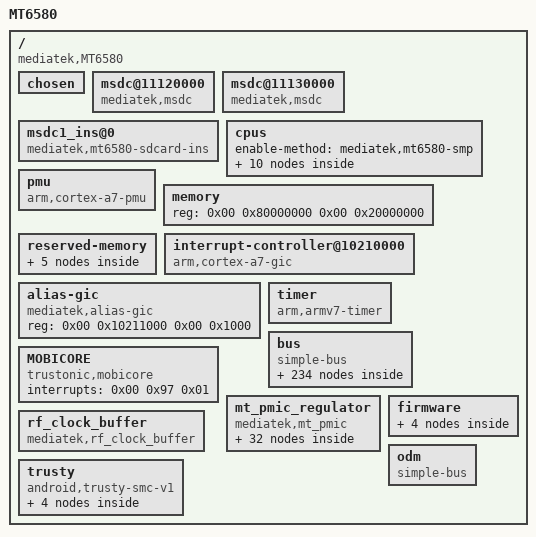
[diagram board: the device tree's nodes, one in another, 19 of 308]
/dts-v1/;

/ {
	model = "MT6580";
	compatible = "mediatek,MT6580";
	interrupt-parent = <0x01>;
	#address-cells = <0x02>;
	#size-cells = <0x02>;

	chosen {
		bootargs = "console=tty0 console=ttyMT3,921600n1 vmalloc=496M androidboot.hardware=mt6580 firmware_class.path=/vendor/firmware loop.max_part=7";
		linux,phandle = <0x2f>;
		phandle = <0x2f>;
	};

	msdc@11120000 {
		compatible = "mediatek,msdc";
		reg = <0x00 0x11120000 0x00 0x10000>;
		interrupts = <0x00 0x26 0x08>;
		index = [00];
		clk_src = [02];
		bus-width = <0x08>;
		max-frequency = <0xbebc200>;
		cap-mmc-highspeed;
		mmc-ddr-1_8v;
		mmc-hs200-1_8v;
		no-sd;
		no-sdio;
		non-removable;
		pinctl = <0x02>;
		pinctl_hs200 = <0x03>;
		register_setting = <0x04>;
		host_function = [00];
		bootable;
		status = "okay";
		vmmc-supply = <0x05>;
		linux,phandle = <0x30>;
		phandle = <0x30>;
	};

	msdc@11130000 {
		compatible = "mediatek,msdc";
		reg = <0x00 0x11130000 0x00 0x10000>;
		interrupts = <0x00 0x27 0x08>;
		index = [01];
		clk_src = [02];
		bus-width = <0x04>;
		max-frequency = <0xbebc200>;
		cap-sd-highspeed;
		sd-uhs-sdr12;
		sd-uhs-sdr25;
		sd-uhs-sdr50;
		sd-uhs-sdr104;
		sd-uhs-ddr50;
		no-mmc;
		no-sdio;
		pinctrl-names = "default\0insert_cfg";
		pinctrl-0 = <0x06>;
		pinctrl-1 = <0x07>;
		pinctl = <0x08>;
		pinctl_sdr104 = <0x09>;
		pinctl_sdr50 = <0x0a>;
		pinctl_ddr50 = <0x0b>;
		register_setting = <0x0c>;
		host_function = [01];
		cd_level = [00];
		cd-gpios = <0x0d 0x03 0x00>;
		status = "okay";
		vmmc-supply = <0x0e>;
		vqmmc-supply = <0x0f>;
		linux,phandle = <0x31>;
		phandle = <0x31>;
	};

	msdc1_ins@0 {
		compatible = "mediatek,mt6580-sdcard-ins";
		linux,phandle = <0x32>;
		phandle = <0x32>;
	};

	cpus {
		#address-cells = <0x01>;
		#size-cells = <0x00>;
		enable-method = "mediatek,mt6580-smp";

		cpu@0 {
			device_type = "cpu";
			compatible = "arm,cortex-a7";
			reg = <0x00>;
			clock-frequency = <0x6553f100>;
			linux,phandle = <0x10>;
			phandle = <0x10>;
		};

		cpu@1 {
			device_type = "cpu";
			compatible = "arm,cortex-a7";
			reg = <0x01>;
			clock-frequency = <0x6553f100>;
			linux,phandle = <0x11>;
			phandle = <0x11>;
		};

		cpu@2 {
			device_type = "cpu";
			compatible = "arm,cortex-a7";
			reg = <0x02>;
			clock-frequency = <0x6553f100>;
			linux,phandle = <0x12>;
			phandle = <0x12>;
		};

		cpu@3 {
			device_type = "cpu";
			compatible = "arm,cortex-a7";
			reg = <0x03>;
			clock-frequency = <0x6553f100>;
			linux,phandle = <0x13>;
			phandle = <0x13>;
		};

		cpu-map {

			cluster0 {

				core0 {
					cpu = <0x10>;
				};

				core1 {
					cpu = <0x11>;
				};

				core2 {
					cpu = <0x12>;
				};

				core3 {
					cpu = <0x13>;
				};
			};
		};
	};

	pmu {
		compatible = "arm,cortex-a7-pmu";
		interrupts = <0x00 0x04 0x08 0x00 0x05 0x08 0x00 0x06 0x08 0x00 0x07 0x08>;
	};

	memory {
		device_type = "memory";
		reg = <0x00 0x80000000 0x00 0x20000000>;
	};

	reserved-memory {
		#address-cells = <0x02>;
		#size-cells = <0x02>;
		ranges;
		linux,phandle = <0x33>;
		phandle = <0x33>;

		consys-reserve-memory {
			compatible = "mediatek,consys-reserve-memory";
			no-map;
			size = <0x00 0x200000>;
			alignment = <0x00 0x200000>;
		};

		reserve-memory-ccci_md1 {
			compatible = "mediatek,reserve-memory-ccci_md1";
			no-map;
			size = <0x00 0x1800000>;
			alignment = <0x00 0x2000000>;
			alloc-ranges = <0x00 0x80000000 0x00 0x80000000>;
		};

		pstore-reserved-memory@83f10000 {
			compatible = "mediatek,pstore";
			reg = <0x00 0x83f10000 0x00 0xe0000>;
		};

		ram_console-reserved-memory@83f00000 {
			compatible = "mediatek,ram_console";
			reg = <0x00 0x83f00000 0x00 0x10000>;
		};

		minirdump-reserved-memory@83ff0000 {
			compatible = "mediatek, minirdump";
			reg = <0x00 0x83ff0000 0x00 0x10000>;
		};
	};

	interrupt-controller@10210000 {
		compatible = "arm,cortex-a7-gic";
		#interrupt-cells = <0x03>;
		#address-cells = <0x00>;
		interrupt-controller;
		reg = <0x00 0x10211000 0x00 0x1000 0x00 0x10212000 0x00 0x1000 0x00 0x10200100 0x00 0x1000>;
		interrupts = <0x01 0x09 0xf04>;
		linux,phandle = <0x01>;
		phandle = <0x01>;
	};

	alias-gic {
		compatible = "mediatek,alias-gic";
		reg = <0x00 0x10211000 0x00 0x1000>;
	};

	timer {
		compatible = "arm,armv7-timer";
		interrupts = <0x01 0x0d 0x08 0x01 0x0e 0x08 0x01 0x0b 0x08 0x01 0x0a 0x08>;
		clock-frequency = <0xc65d40>;
	};

	bus {
		compatible = "simple-bus";
		#address-cells = <0x01>;
		#size-cells = <0x01>;
		ranges = <0x00 0x00 0x00 0xffffffff>;
		linux,phandle = <0x34>;
		phandle = <0x34>;

		chipid@08000000 {
			compatible = "mediatek,chipid";
			reg = <0x8000000 0x04 0x8000004 0x04 0x8000008 0x04 0x800000c 0x04>;
		};

		TOPCKGEN@0x10000000 {
			compatible = "mediatek,TOPCKGEN";
			reg = <0x10000000 0x1000>;
		};

		INFRACFG_AO@0x10001000 {
			compatible = "mediatek,INFRACFG_AO";
			reg = <0x10001000 0x1000>;
		};

		bat_meter {
			compatible = "mediatek,bat_meter";
			linux,phandle = <0x35>;
			phandle = <0x35>;
		};

		BAT_NOTIFY {
			compatible = "mediatek,bat_notify";
		};

		bat_comm {
			compatible = "mediatek,battery";
			linux,phandle = <0x36>;
			phandle = <0x36>;
		};

		keypad@10002000 {
			compatible = "mediatek,kp";
			reg = <0x10002000 0x1000>;
			interrupts = <0x00 0x6d 0x02>;
			linux,phandle = <0x37>;
			phandle = <0x37>;
		};

		PERICFG@0x10003000 {
			compatible = "mediatek,PERICFG";
			reg = <0x10003000 0x1000>;
		};

		RESERVED@0x10004000 {
			compatible = "mediatek,RESERVED";
			reg = <0x10004000 0x1000>;
		};

		gpio {
			compatible = "mediatek,gpio_usage_mapping";
			linux,phandle = <0x38>;
			phandle = <0x38>;
		};

		gpio@0x10005000 {
			compatible = "mediatek,gpio";
			reg = <0x10005000 0x1000>;
			linux,phandle = <0x39>;
			phandle = <0x39>;
		};

		SLEEP@0x10006000 {
			compatible = "mediatek,SLEEP";
			reg = <0x10006000 0x1000>;
			interrupts = <0x00 0x58 0x08 0x00 0x59 0x08 0x00 0x5a 0x08 0x00 0x5b 0x08>;
		};

		TOPRGU@0x10007000 {
			compatible = "mediatek,TOPRGU";
			reg = <0x10007000 0x1000>;
			interrupts = <0x00 0x9d 0x02>;
		};

		APXGPT@0x10008000 {
			compatible = "mediatek,APXGPT";
			reg = <0x10008000 0x1000>;
			interrupts = <0x00 0x5c 0x08>;
			clock-frequency = <0xc65d40>;
		};

		EFUSEC@0x10009000 {
			compatible = "mediatek,EFUSEC";
			reg = <0x10009000 0x1000>;
		};

		hacc@0x1000A000 {
			compatible = "mediatek,hacc";
			reg = <0x1000a000 0x1000>;
			interrupts = <0x00 0x6e 0x00>;
		};

		cpu_dbgapb@10170000 {
			compatible = "mediatek,hw_dbg";
			num = <0x04>;
			reg = <0x10170000 0x2000 0x10172000 0x2000 0x10174000 0x2000 0x10176000 0x2000>;
			linux,phandle = <0x3a>;
			phandle = <0x3a>;
		};

		eintc@1000b000 {
			compatible = "mediatek,mt-eic";
			reg = <0x1000b000 0x1000>;
			interrupts = <0x00 0x5e 0x04>;
			#interrupt-cells = <0x02>;
			interrupt-controller;
			mediatek,max_eint_num = <0x1a>;
			mediatek,mapping_table_entry = <0x53>;
			mediatek,mapping_table = <0x00 0x00 0x01 0x01 0x02 0x02 0x03 0x03 0x04 0x04 0x05 0x05 0x06 0x06 0x07 0x07 0x08 0x08 0x09 0x09 0x0a 0x0a 0x0b 0x0b 0x0c 0x0c 0x0d 0x0d 0x0e 0x0e 0x0f 0x0f 0x10 0x00 0x11 0x01 0x12 0x02 0x13 0x03 0x14 0x04 0x15 0x05 0x16 0x06 0x17 0x07 0x18 0x08 0x19 0x09 0x1a 0x0a 0x1b 0x0b 0x1c 0x0c 0x1d 0x0d 0x1e 0x0e 0x1f 0x0f 0x20 0x00 0x21 0x01 0x22 0x02 0x23 0x03 0x24 0x04 0x25 0x05 0x26 0x06 0x27 0x07 0x28 0x08 0x29 0x09 0x2a 0x0a 0x2b 0x0b 0x2c 0x0c 0x2d 0x0d 0x2e 0x0e 0x2f 0x0f 0x30 0x00 0x31 0x01 0x32 0x02 0x33 0x03 0x34 0x03 0x35 0x04 0x36 0x05 0x37 0x06 0x38 0x07 0x39 0x08 0x3a 0x0a 0x3b 0x0b 0x3c 0x0c 0x3d 0x0d 0x3e 0x0e 0x3f 0x0f 0x40 0x00 0x41 0x01 0x42 0x02 0x43 0x03 0x44 0x10 0x45 0x04 0x46 0x05 0x47 0x06 0x48 0x07 0x49 0x08 0x4a 0x09 0x4b 0x0a 0x4c 0x0b 0x4d 0x0c 0x4e 0x0d 0x51 0x00 0x52 0x01 0x53 0x02 0x54 0x03>;
			mediatek,builtin_entry = <0x0b>;
			mediatek,builtin_mapping = <0x00 0x03 0x14 0x01 0x03 0x12 0x07 0x04 0x14 0x08 0x04 0x12 0x09 0x03 0x14 0x0a 0x03 0x12 0x18 0x05 0x14 0x19 0x05 0x12 0x4d 0x02 0x14 0x4e 0x02 0x12 0x0d 0x01 0x11>;
			linux,phandle = <0x14>;
			phandle = <0x14>;

			pmic@13 {
				compatible = "mediatek, pmic-eint";
				interrupt-parent = <0x14>;
				interrupts = <0x0d 0x04>;
				debounce = <0x0d 0x3e8>;
			};
		};

		ap_ccif0@1000C000 {
			compatible = "mediatek,ap_ccif0";
			reg = <0x1000c000 0x1000 0x1000d000 0x1000>;
			interrupts = <0x00 0x5d 0x08 0x00 0x98 0x02>;
			mediatek,ccif_capability = <0x02>;
			mediatek,md_smem_size = <0x200000>;
			linux,phandle = <0x3b>;
			phandle = <0x3b>;
		};

		MCUSYS_CFGREG@0x1020000 {
			compatible = "mediatek,MCUSYS_CFGREG_BASE";
			reg = <0x1020000 0x200>;
		};

		mcucfg@10200000 {
			compatible = "mediatek,mt6580-mcucfg";
			reg = <0x10200000 0x200>;
			linux,phandle = <0x3c>;
			phandle = <0x3c>;
		};

		AES@0x1000E000 {
			compatible = "mediatek,AES";
			reg = <0x1000e000 0x1000>;
		};

		PWRAP@0x1000F000 {
			compatible = "mediatek,PWRAP";
			reg = <0x1000f000 0x1000>;
			interrupts = <0x00 0x6c 0x00>;
		};

		DEVAPC_AO@0x10010000 {
			compatible = "mediatek,DEVAPC_AO";
			reg = <0x10010000 0x1000>;
		};

		MIPI_CONFG@0x10011000 {
			compatible = "mediatek,MIPI_CONFG";
			reg = <0x10011000 0x1000>;
		};

		INFRA_MBIST@0x10012000 {
			compatible = "mediatek,INFRA_MBIST";
			reg = <0x10012000 0x1000>;
		};

		RESERVED@0x10013000 {
			compatible = "mediatek,RESERVED";
			reg = <0x10013000 0x1000>;
		};

		IOCFG_T@0x10014000 {
			compatible = "mediatek,IOCFG_T";
			reg = <0x10014000 0x1000>;
		};

		IOCFG_B@0x10015000 {
			compatible = "mediatek,IOCFG_B";
			reg = <0x10015000 0x1000>;
		};

		IOCFG_L@0x10016000 {
			compatible = "mediatek,IOCFG_L";
			reg = <0x10016000 0x1000>;
		};

		IOCFG_R@0x10017000 {
			compatible = "mediatek,IOCFG_R";
			reg = <0x10017000 0x1000>;
		};

		APMIXED@0x10018000 {
			compatible = "mediatek,APMIXED";
			reg = <0x10018000 0x1000>;
		};

		MCUCFG@0x10200000 {
			compatible = "mediatek,MCUCFG";
			reg = <0x10200000 0x1000>;
		};

		INFRACFG@0x10201000 {
			compatible = "mediatek,INFRACFG";
			reg = <0x10201000 0x1000>;
		};

		sys_cirq@10202000 {
			compatible = "mediatek,mt6580-sys_cirq\0mediatek,mt6735-sys_cirq";
			reg = <0x10202000 0x1000>;
			interrupts = <0x00 0x9e 0x08>;
			mediatek,cirq_num = <0x7e>;
			mediatek,spi_start_offset = <0x20>;
			linux,phandle = <0x3d>;
			phandle = <0x3d>;
		};

		m4u@10203000 {
			cell-index = <0x00>;
			compatible = "mediatek,m4u";
			reg = <0x10203000 0x1000>;
			interrupts = <0x00 0x51 0x08>;
		};

		DEVAPC@0x10204000 {
			compatible = "mediatek,DEVAPC";
			reg = <0x10204000 0x1000>;
			interrupts = <0x00 0x4a 0x08>;
		};

		EMI@0x10205000 {
			compatible = "mediatek,EMI";
			reg = <0x10205000 0x1000>;
			interrupts = <0x00 0x4c 0x04>;
		};

		DRAMC_NAO@0x10206000 {
			compatible = "mediatek,DRAMC_NAO";
			reg = <0x10206000 0x1000>;
		};

		DRAMC0@0x10207000 {
			compatible = "mediatek,DRAMC0";
			reg = <0x10207000 0x1000>;
		};

		DDRPHY@0x10208000 {
			compatible = "mediatek,DDRPHY";
			reg = <0x10208000 0x1000>;
		};

		SRAMROM@0x10209000 {
			compatible = "mediatek,SRAMROM";
			reg = <0x10209000 0x1000>;
		};

		gce@1020a000 {
			compatible = "mediatek,gce";
			reg = <0x1020a000 0x1000>;
			interrupts = <0x00 0x55 0x08 0x00 0x56 0x08>;
			disp_mutex_reg = <0x14015000 0x1000>;
			g3d_config_base = <0x13000000 0x00 0xffff0000>;
			mmsys_config_base = <0x14000000 0x01 0xffff0000>;
			disp_dither_base = <0x14010000 0x02 0xffff0000>;
			mm_na_base = <0x14020000 0x03 0xffff0000>;
			imgsys_base = <0x15000000 0x04 0xffff0000>;
			vdec_gcon_base = <0x16000000 0x05 0xffff0000>;
			venc_gcon_base = <0x17000000 0x06 0xffff0000>;
			conn_peri_base = <0x18000000 0x07 0xffff0000>;
			topckgen_base = <0x10000000 0x08 0xffff0000>;
			kp_base = <0x10010000 0x09 0xffff0000>;
			scp_sram_base = <0x10020000 0x0a 0xffff0000>;
			infra_na3_base = <0x10030000 0x0b 0xffff0000>;
			infra_na4_base = <0x10040000 0x0c 0xffff0000>;
			scp_base = <0x10050000 0x0d 0xffff0000>;
			mcucfg_base = <0x10200000 0x0e 0xffff0000>;
			gcpu_base = <0x10210000 0x0f 0xffff0000>;
			usb0_base = <0x11200000 0x10 0xffff0000>;
			usb_sif_base = <0x11210000 0x11 0xffff0000>;
			audio_base = <0x11220000 0x12 0xffff0000>;
			msdc0_base = <0x11230000 0x13 0xffff0000>;
			msdc1_base = <0x11240000 0x14 0xffff0000>;
			msdc2_base = <0x11250000 0x15 0xffff0000>;
			msdc3_base = <0x11260000 0x16 0xffff0000>;
			pwm_sw_base = <0x1100f000 0x63 0xfffff000>;
			mdp_rdma0_sof = <0x00>;
			mdp_rsz0_sof = <0x01>;
			mdp_rsz1_sof = <0x02>;
			mdp_tdshp_sof = <0x03>;
			mdp_wdma_sof = <0x04>;
			mdp_wrot_sof = <0x05>;
			disp_ovl0_sof = <0x06>;
			disp_rdma0_sof = <0x08>;
			disp_wdma0_sof = <0x0a>;
			disp_color_sof = <0x0c>;
			disp_aal_sof = <0x0d>;
			disp_gamma_sof = <0x0e>;
			disp_dither_sof = <0x0f>;
			disp_pwm0_sof = <0x11>;
			mdp_rdma0_frame_done = <0x12>;
			mdp_rsz0_frame_done = <0x13>;
			mdp_rsz1_frame_done = <0x14>;
			mdp_tdshp_frame_done = <0x15>;
			mdp_wdma_frame_done = <0x16>;
			mdp_wrot_write_frame_done = <0x17>;
			mdp_wrot_read_frame_done = <0x18>;
			disp_ovl0_frame_done = <0x19>;
			disp_rdma0_frame_done = <0x1b>;
			disp_wdma0_frame_done = <0x1d>;
			disp_color_frame_done = <0x1f>;
			disp_aal_frame_done = <0x20>;
			disp_gamma_frame_done = <0x21>;
			disp_dither_frame_done = <0x22>;
			disp_dsi0_frame_done = <0x25>;
			stream_done_0 = <0x26>;
			stream_done_1 = <0x27>;
			stream_done_2 = <0x28>;
			stream_done_3 = <0x29>;
			stream_done_4 = <0x2a>;
			stream_done_5 = <0x2b>;
			stream_done_6 = <0x2c>;
			stream_done_7 = <0x2d>;
			stream_done_8 = <0x2e>;
			stream_done_9 = <0x2f>;
			buf_underrun_event_0 = <0x30>;
			dsi0_te_event = <0x32>;
			isp_frame_done_p2_1 = <0x42>;
			isp_frame_done_p2_0 = <0x43>;
			seninf_cam0_fifo_full = <0x49>;
			apxgpt2_count = <0x10008028>;
		};

		bus_dbg@1020b000 {
			compatible = "mediatek,bus_dbg-v2";
			reg = <0x1020b000 0x1000>;
			interrupts = <0x00 0x49 0x08>;
			two_stage_timeout = <0x01>;
		};

		trng@0x1020f000 {
			compatible = "mediatek,trng";
			reg = <0x1020c000 0x1000 0x10001000 0x1000>;
			interrupts = <0x00 0x57 0x08>;
		};

		MCUCFG_BIU@0x1020D000 {
			compatible = "mediatek,MCUCFG_BIU";
			reg = <0x1020d000 0x1000>;
		};

		DBGSYS_DEM@0x1011A000 {
			compatible = "mediatek,DBGSYS_DEM";
			reg = <0x1011a000 0x1000>;
		};

		DBGSYS_CTI@0x10112000 {
			compatible = "mediatek,DBGSYS_CTI";
			reg = <0x10112000 0x1000>;
		};

		DBGSYS_DAPROM@0x10110000 {
			compatible = "mediatek,DBGSYS_DAPROM";
			reg = <0x10110000 0x1000>;
		};

		DBGSYS_CPU@0x10160000 {
			compatible = "mediatek,DBGSYS_CPU";
			reg = <0x10160000 0x20000>;
		};

		DBGSYS_MDSYS@0x10120000 {
			compatible = "mediatek,DBGSYS_MDSYS";
			reg = <0x10120000 0x10000>;
		};

		dma@0x11000000 {
			compatible = "mediatek,ap_dma";
			reg = <0x11000000 0x1000>;
			interrupts = <0x00 0x30 0x08>;
			linux,phandle = <0x3e>;
			phandle = <0x3e>;
		};

		NFI@0x11001000 {
			compatible = "mediatek,NFI";
			reg = <0x11001000 0x1000>;
			interrupts = <0x00 0x2f 0x08>;
		};

		NFIECC@0x11002000 {
			compatible = "mediatek,NFIECC";
			reg = <0x11002000 0x1000>;
			interrupts = <0x00 0x2e 0x08>;
		};

		adc_hw@11003000 {
			compatible = "mediatek,mt6735-auxadc";
			reg = <0x11003000 0x1000>;
			interrupts = <0x00 0x23 0x02>;
			linux,phandle = <0x3f>;
			phandle = <0x3f>;
		};

		FHCTL@0x11004000 {
			compatible = "mediatek,FHCTL";
			reg = <0x11004000 0x1000>;
		};

		AP_UART0@0x11005000 {
			cell-index = <0x00>;
			skip_pinmux_clk = <0x01>;
			compatible = "mediatek,AP_UART0";
			reg = <0x11005000 0x1000>;
			interrupts = <0x00 0x2c 0x08>;
		};

		AP_UART1@0x11006000 {
			cell-index = <0x01>;
			skip_pinmux_clk = <0x01>;
			compatible = "mediatek,AP_UART1";
			reg = <0x11006000 0x1000>;
			interrupts = <0x00 0x2d 0x08>;
		};

		AP_DMA_UART0_TX@0x11000480 {
			compatible = "mediatek,AP_DMA_UART0_TX";
			reg = <0x11000480 0x80>;
			interrupts = <0x00 0x38 0x08>;
		};

		AP_DMA_UART0_RX@0x11000500 {
			compatible = "mediatek,AP_DMA_UART0_RX";
			reg = <0x11000500 0x80>;
			interrupts = <0x00 0x39 0x08>;
		};

		AP_DMA_UART1_TX@0x11000580 {
			compatible = "mediatek,AP_DMA_UART1_TX";
			reg = <0x11000580 0x80>;
			interrupts = <0x00 0x3a 0x08>;
		};

		AP_DMA_UART1_RX@0x11000600 {
			compatible = "mediatek,AP_DMA_UART1_RX";
			reg = <0x11000600 0x80>;
			interrupts = <0x00 0x3b 0x08>;
		};

		pwm@11008000 {
			compatible = "mediatek,pwm";
			reg = <0x11008000 0x1000>;
			interrupts = <0x00 0x24 0x08>;
		};

		syscfg_pctl_a@0x10005000 {
			compatible = "mediatek,mt6580-pctl-a-syscfg\0syscon";
			reg = <0x10211000 0x1000>;
			linux,phandle = <0x15>;
			phandle = <0x15>;
		};

		pinctrl@0x10005000 {
			compatible = "mediatek,mt6580-pinctrl";
			reg = <0x10005000 0x1000>;
			mediatek,pctl-regmap = <0x15>;
			pins-are-numbered;
			gpio-controller;
			#gpio-cells = <0x02>;
			linux,phandle = <0x0d>;
			phandle = <0x0d>;

			msdc0@default {
				linux,phandle = <0x02>;
				phandle = <0x02>;

				pins_cmd {
					drive-strength = [02];
				};

				pins_dat {
					drive-strength = [02];
				};

				pins_clk {
					drive-strength = [02];
				};

				pins_rst {
					drive-strength = [02];
				};

				pins_ds {
					drive-strength = [02];
				};
			};

			msdc0@hs200 {
				linux,phandle = <0x03>;
				phandle = <0x03>;

				pins_cmd {
					drive-strength = [02];
				};

				pins_dat {
					drive-strength = [02];
				};

				pins_clk {
					drive-strength = [02];
				};

				pins_rst {
					drive-strength = [02];
				};

				pins_ds {
					drive-strength = [02];
				};
			};

			msdc0@register_default {
				cmd_edge = [00];
				rdata_edge = [00];
				wdata_edge = [00];
				linux,phandle = <0x04>;
				phandle = <0x04>;
			};

			mmc1_ins_default {
				linux,phandle = <0x06>;
				phandle = <0x06>;
			};

			mmc1_ins_cfg {
				linux,phandle = <0x07>;
				phandle = <0x07>;

				pins_insert {
					pins = <0x306>;
					input-schmitt-enable = <0x01>;
					slew-rate = <0x00>;
					bias-pull-up = <0x00>;
				};
			};

			msdc1@default {
				linux,phandle = <0x08>;
				phandle = <0x08>;

				pins_cmd {
					drive-strength = [03];
				};

				pins_dat {
					drive-strength = [03];
				};

				pins_clk {
					drive-strength = [03];
				};
			};

			msdc1@sdr104 {
				linux,phandle = <0x09>;
				phandle = <0x09>;

				pins_cmd {
					drive-strength = [02];
				};

				pins_dat {
					drive-strength = [02];
				};

				pins_clk {
					drive-strength = [03];
				};
			};

			msdc1@sdr50 {
				linux,phandle = <0x0a>;
				phandle = <0x0a>;

				pins_cmd {
					drive-strength = [02];
				};

				pins_dat {
					drive-strength = [02];
				};

				pins_clk {
					drive-strength = [03];
				};
			};

			msdc1@ddr50 {
				linux,phandle = <0x0b>;
				phandle = <0x0b>;

				pins_cmd {
					drive-strength = [02];
				};

				pins_dat {
					drive-strength = [02];
				};

				pins_clk {
					drive-strength = [03];
				};
			};

			msdc1@register_default {
				cmd_edge = [00];
				rdata_edge = [00];
				wdata_edge = [00];
				linux,phandle = <0x0c>;
				phandle = <0x0c>;
			};
		};

		i2c@11009000 {
			compatible = "mediatek,mt6580-i2c\0mediatek,i2c0";
			cell-index = <0x00>;
			reg = <0x11009000 0x1000>;
			interrupts = <0x00 0x28 0x08 0x00 0x32 0x08>;
			clock-div = <0x0a>;
			#address-cells = <0x01>;
			#size-cells = <0x00>;
			linux,phandle = <0x40>;
			phandle = <0x40>;
		};

		i2c@1100a000 {
			compatible = "mediatek,mt6580-i2c\0mediatek,i2c1";
			cell-index = <0x01>;
			reg = <0x1100a000 0x1000>;
			interrupts = <0x00 0x29 0x08 0x00 0x33 0x08>;
			clock-div = <0x0a>;
			#address-cells = <0x01>;
			#size-cells = <0x00>;
			linux,phandle = <0x41>;
			phandle = <0x41>;
		};

		i2c@1100b000 {
			compatible = "mediatek,mt6580-i2c\0mediatek,i2c2";
			cell-index = <0x02>;
			reg = <0x1100b000 0x1000>;
			interrupts = <0x00 0x2a 0x08 0x00 0x34 0x08>;
			clock-div = <0x0a>;
			#address-cells = <0x01>;
			#size-cells = <0x00>;
			linux,phandle = <0x42>;
			phandle = <0x42>;
		};

		touch@0 {
			compatible = "mediatek,touch";
			vtouch-supply = <0x16>;
			linux,phandle = <0x43>;
			phandle = <0x43>;
		};

		accdet {
			compatible = "mediatek,pmic-accdet";
			linux,phandle = <0x44>;
			phandle = <0x44>;
		};

		gse_1 {
			compatible = "mediatek, gse_1-eint";
			status = "disabled";
			linux,phandle = <0x45>;
			phandle = <0x45>;
		};

		spi@1100c000 {
			compatible = "mediatek,mt6580-spi";
			cell-index = <0x00>;
			reg = <0x1100c000 0x1000>;
			interrupts = <0x00 0x40 0x08>;
			mediatek,spi-padmacro = <0x00>;
		};

		THERM_CTRL@0x1100D000 {
			compatible = "mediatek,THERM_CTRL";
			reg = <0x1100d000 0x1000>;
			interrupts = <0x00 0x25 0x08>;
		};

		btif@1100e000 {
			compatible = "mediatek,btif";
			#address-cells = <0x02>;
			#size-cells = <0x02>;
			reg = <0x1100e000 0x1000 0x11000380 0x80 0x11000400 0x80>;
			interrupts = <0x00 0x43 0x08 0x00 0x36 0x08 0x00 0x37 0x08>;
		};

		gps {
			compatible = "mediatek,gps";
		};

		BTCVSD@0x10001000 {
			compatible = "mediatek,audio_bt_cvsd";
			offset = <0xc00 0x02 0xfd0 0xfd4 0xfd8>;
			reg = <0x10001000 0x1000 0x18000000 0x10000 0x18080000 0x8000>;
			interrupts = <0x00 0x99 0x08>;
		};

		consys@18070000 {
			compatible = "mediatek,mt6580-consys";
			reg = <0x18070000 0x200 0x10007000 0x100 0x10000000 0x2000 0x10006000 0x1000 0x10005000 0x1000>;
			interrupts = <0x00 0x9a 0x08 0x00 0x9c 0x08>;
			vcn18-supply = <0x17>;
			vcn28-supply = <0x18>;
			vcn33_bt-supply = <0x19>;
			vcn33_wifi-supply = <0x1a>;
			linux,phandle = <0x46>;
			phandle = <0x46>;
		};

		WIFI@0x180F0000 {
			compatible = "mediatek,WIFI";
			reg = <0x180f0000 0x5c>;
			interrupts = <0x00 0x9b 0x08>;
		};

		DISP_PWM@0x1100F000 {
			compatible = "mediatek,DISP_PWM";
			reg = <0x1100f000 0x1000>;
			interrupts = <0x00 0x21 0x08>;
		};

		USB0@0x11100000 {
			compatible = "mediatek,USB0";
			cell-index = <0x00>;
			reg = <0x11100000 0x10000 0x11110000 0x10000>;
			interrupts = <0x00 0x20 0x08>;
			mode = <0x02>;
			multipoint = <0x01>;
			dyn_fifo = <0x01>;
			soft_con = <0x01>;
			dma = <0x01>;
			num_eps = <0x10>;
			dma_channels = <0x08>;
			linux,phandle = <0x47>;
			phandle = <0x47>;
		};

		usbiddig {
			compatible = "mediatek,usb_iddig_eint";
			linux,phandle = <0x48>;
			phandle = <0x48>;
		};

		usbphy@0 {
			compatible = "usb-nop-xceiv";
			linux,phandle = <0x49>;
			phandle = <0x49>;
		};

		audio@11140000 {
			compatible = "mediatek,audio";
			reg = <0x11140000 0x10000>;
			interrupts = <0x00 0x50 0x08>;
		};

		mt_soc_dl1_pcm@11140000 {
			compatible = "mediatek,mt_soc_pcm_dl1";
			reg = <0x11140000 0x1000>;
			interrupts = <0x00 0x50 0x08>;
			audclk-gpio = <0x1a 0x00>;
			audmiso-gpio = <0x1c 0x00>;
			audmosi-gpio = <0x1b 0x00>;
			linux,phandle = <0x4a>;
			phandle = <0x4a>;
		};

		mt_soc_ul1_PCM {
			compatible = "mediatek,mt_soc_pcm_capture";
		};

		mt_soc_voice_md1 {
			compatible = "mediatek,mt_soc_pcm_voice_md1";
		};

		mt_soc_hdmi_pcm {
			compatible = "mediatek,mt_soc_pcm_hdmi";
		};

		mt_soc_uldlloopback_pcm {
			compatible = "mediatek,mt_soc_pcm_uldlloopback";
		};

		mt_soc_i2s0_pcm {
			compatible = "mediatek,mt_soc_pcm_dl1_i2s0";
		};

		mt_soc_mrgrx_pcm {
			compatible = "mediatek,mt_soc_pcm_mrgrx";
		};

		mt_soc_mrgrx_awb_pcm {
			compatible = "mediatek,mt_soc_pcm_mrgrx_awb";
		};

		mt_soc_fm_i2s_pcm {
			compatible = "mediatek,mt_soc_pcm_fm_i2s";
		};

		mt_soc_fm_i2s_awb_pcm {
			compatible = "mediatek,mt_soc_pcm_fm_i2s_awb";
		};

		mt_soc_i2s0dl1_pcm {
			compatible = "mediatek,mt_soc_pcm_dl1_i2s0Dl1";
		};

		mt_soc_deep_buffer_dl_pcm {
			compatible = "mediatek,mt_soc_pcm_deep_buffer_dl";
		};

		mt_soc_dl1_awb_pcm {
			compatible = "mediatek,mt_soc_pcm_dl1_awb";
		};

		mt_soc_voice_md1_bt {
			compatible = "mediatek,mt_soc_pcm_voice_md1_bt";
		};

		mt_soc_voip_bt_out {
			compatible = "mediatek,mt_soc_pcm_dl1_bt";
		};

		mt_soc_voip_bt_in {
			compatible = "mediatek,mt_soc_pcm_bt_dai";
		};

		mt_soc_tdmrx_pcm {
			compatible = "mediatek,mt_soc_tdm_capture";
		};

		mt_soc_fm_mrgtx_pcm {
			compatible = "mediatek,mt_soc_pcm_fmtx";
		};

		mt_soc_ul2_pcm {
			compatible = "mediatek,mt_soc_pcm_capture2";
		};

		mt_soc_i2s0_awb_pcm {
			compatible = "mediatek,mt_soc_pcm_i2s0_awb";
		};

		mt_soc_voice_md2 {
			compatible = "mediatek,mt_soc_pcm_voice_md2";
		};

		mt_soc_routing_pcm {
			compatible = "mediatek,mt_soc_pcm_routing";
		};

		mt_soc_voice_md2_bt {
			compatible = "mediatek,mt_soc_pcm_voice_md2_bt";
		};

		mt_soc_hp_impedance_pcm {
			compatible = "mediatek,Mt_soc_pcm_hp_impedance";
		};

		mt_soc_codec_name {
			compatible = "mediatek,mt_soc_codec_63xx";
		};

		mt_soc_dummy_pcm {
			compatible = "mediatek,mt_soc_pcm_dummy";
		};

		mt_soc_codec_dummy_name {
			compatible = "mediatek,mt_soc_codec_dummy";
		};

		mt_soc_routing_dai_name {
			compatible = "mediatek,mt_soc_dai_routing";
		};

		mt_soc_dai_name {
			compatible = "mediatek,mt_soc_dai_stub";
		};

		mt_soc_dl2_pcm {
			compatible = "mediatek,mt_soc_pcm_dl2";
		};

		AHB_MOM@0x11150000 {
			compatible = "mediatek,AHB_MOM";
			reg = <0x11150000 0x10000>;
		};

		MDI@0x11160000 {
			compatible = "mediatek,MDI";
			reg = <0x11160000 0x10000>;
		};

		G3D_CONFIG@0x13000000 {
			compatible = "mediatek,G3D_CONFIG";
			reg = <0x13000000 0x1000>;
		};

		MALI@0x13010000 {
			compatible = "mediatek,MALI";
			reg = <0x13010000 0x10000>;
		};

		mmsys_config@14000000 {
			compatible = "mediatek,mmsys_config";
			reg = <0x14000000 0x1000>;
			interrupts = <0x00 0x84 0x08>;
			linux,phandle = <0x1d>;
			phandle = <0x1d>;
		};

		mdp_rdma@14001000 {
			compatible = "mediatek,mdp_rdma";
			reg = <0x14001000 0x1000>;
			interrupts = <0x00 0x71 0x08>;
		};

		mdp_rsz0@14002000 {
			compatible = "mediatek,mdp_rsz0";
			reg = <0x14002000 0x1000>;
			interrupts = <0x00 0x72 0x08>;
		};

		mdp_rsz1@14003000 {
			compatible = "mediatek,mdp_rsz1";
			reg = <0x14003000 0x1000>;
			interrupts = <0x00 0x73 0x08>;
		};

		mdp_wdma@14004000 {
			compatible = "mediatek,mdp_wdma";
			reg = <0x14004000 0x1000>;
			interrupts = <0x00 0x75 0x08>;
		};

		mdp_wrot@14005000 {
			compatible = "mediatek,mdp_wrot";
			reg = <0x14005000 0x1000>;
			interrupts = <0x00 0x76 0x08>;
		};

		mdp_tdshp@14006000 {
			compatible = "mediatek,mdp_tdshp";
			reg = <0x14006000 0x1000>;
			interrupts = <0x00 0x74 0x08>;
		};

		lcm {
			compatible = "mediatek,mt6580-lcm";
			linux,phandle = <0x4b>;
			phandle = <0x4b>;
		};

		nfc {
			compatible = "mediatek,nfc-gpio-v2";
			gpio-ven = <0x0b>;
			gpio-rst = <0x0a>;
			gpio-eint = <0x0c>;
			gpio-irq = <0x09>;
			linux,phandle = <0x4c>;
			phandle = <0x4c>;
		};

		DISPSYS@0x14007000 {
			compatible = "mediatek,DISPSYS";
			reg = <0x14000000 0x1000 0x14007000 0x1000 0x14008000 0x1000 0x14009000 0x1000 0x1400a000 0x1000 0x1400b000 0x1000 0x1400c000 0x1000 0x1400d000 0x1000 0x1400e000 0x1000 0x1400f000 0x1000 0x14010000 0x1000 0x14011000 0x1000 0x14012000 0x1000 0x14013000 0x1000 0x1100f000 0x1000 0x14015000 0x1000 0x14016000 0x1000 0x14017000 0x1000 0x14018000 0x1000>;
			interrupts = <0x00 0x00 0x08 0x00 0x77 0x08 0x00 0x00 0x08 0x00 0x79 0x08 0x00 0x00 0x08 0x00 0x7b 0x08 0x00 0x7c 0x08 0x00 0x00 0x08 0x00 0x7e 0x08 0x00 0x7f 0x08 0x00 0x80 0x08 0x00 0x00 0x08 0x00 0x82 0x08 0x00 0x00 0x08 0x00 0x00 0x08 0x00 0x70 0x08 0x00 0x00 0x08 0x00 0x00 0x08 0x00 0x00 0x08>;
		};

		DISP_OVL0@0x14007000 {
			compatible = "mediatek,DISP_OVL0";
			reg = <0x14007000 0x1000>;
			interrupts = <0x00 0x77 0x08>;
		};

		DISP_OVL1@0x14008000 {
			compatible = "mediatek,DISP_OVL1";
			reg = <0x14008000 0x1000>;
		};

		DISP_RDMA0@0x14009000 {
			compatible = "mediatek,DISP_RDMA0";
			reg = <0x14009000 0x1000>;
			interrupts = <0x00 0x79 0x08>;
		};

		DISP_RDMA1@0x1400A000 {
			compatible = "mediatek,DISP_RDMA1";
			reg = <0x1400a000 0x1000>;
		};

		DISP_WDMA@0x1400B000 {
			compatible = "mediatek,DISP_WDMA";
			reg = <0x1400b000 0x1000>;
			interrupts = <0x00 0x7b 0x08>;
		};

		DISP_COLOR@0x1400C000 {
			compatible = "mediatek,DISP_COLOR";
			reg = <0x1400c000 0x1000>;
			interrupts = <0x00 0x7c 0x08>;
		};

		DISP_CCORR@0x1400D000 {
			compatible = "mediatek,DISP_CCORR";
			reg = <0x1400d000 0x1000>;
		};

		DISP_AAL@0x1400E000 {
			compatible = "mediatek,DISP_AAL";
			reg = <0x1400e000 0x1000>;
			interrupts = <0x00 0x7e 0x08>;
		};

		DISP_GAMMA@0x1400F000 {
			compatible = "mediatek,DISP_GAMMA";
			reg = <0x1400f000 0x1000>;
			interrupts = <0x00 0x7f 0x08>;
		};

		DISP_DITHER@0x14010000 {
			compatible = "mediatek,DISP_DITHER";
			reg = <0x14010000 0x1000>;
			interrupts = <0x00 0x80 0x08>;
		};

		DISP_UFOE@0x14011000 {
			compatible = "mediatek,DISP_UFOE";
			reg = <0x14011000 0x1000>;
		};

		DSI@0x14012000 {
			compatible = "mediatek,DSI";
			reg = <0x14012000 0x1000>;
		};

		DPI@0x14013000 {
			compatible = "mediatek,DPI";
			reg = <0x14013000 0x1000>;
		};

		PTP_FSM@0x1100D000 {
			compatible = "mediatek,PTP_FSM";
			reg = <0x1100d000 0x1000>;
			interrupts = <0x00 0x2b 0x08>;
		};

		MM_MUTEX@0x14015000 {
			compatible = "mediatek,MM_MUTEX";
			reg = <0x14015000 0x1000>;
			interrupts = <0x00 0x70 0x08>;
		};

		SMI_LARB0@0x14016000 {
			cell-index = <0x00>;
			compatible = "mediatek,SMI_LARB0\0mediatek,smi_larb";
			reg = <0x14016000 0x1000>;
			interrupts = <0x00 0x85 0x08>;
			linux,phandle = <0x1b>;
			phandle = <0x1b>;
		};

		SMI_COMMON@0x14017000 {
			compatible = "mediatek,SMI_COMMON\0mediatek,smi_common";
			reg = <0x14017000 0x1000>;
			nr_larbs = <0x02>;
			larbs = <0x1b 0x1c>;
			mmsys_config = <0x1d>;
		};

		MIPI_TX_CONFIG@0x14018000 {
			compatible = "mediatek,MIPI_TX_CONFIG";
			reg = <0x14018000 0x1000>;
		};

		ISPSYS@0x15000000 {
			compatible = "mediatek,ISPSYS";
			reg = <0x15004000 0x9000 0x15000000 0x10000 0x10011000 0x4000 0x10017000 0x1000>;
			interrupts = <0x00 0x8e 0x08 0x00 0x8b 0x08>;
		};

		ISP_SYSR@0x15000000 {
			compatible = "mediatek,ISP_SYSR";
		};

		ISP_PIPEM@0x15000000 {
			compatible = "mediatek,ISP_PIPEM";
		};

		kd_camera_hw1@15008000 {
			compatible = "mediatek,camera_hw";
			reg = <0x15008000 0x1000>;
			vcama-supply = <0x1e>;
			vcamd-supply = <0x1f>;
			vcamaf-supply = <0x20>;
			vcamio-supply = <0x21>;
			linux,phandle = <0x4d>;
			phandle = <0x4d>;
		};

		kd_camera_hw2@15008000 {
			compatible = "mediatek,camera_hw2";
			reg = <0x15008000 0x1000>;
			linux,phandle = <0x4e>;
			phandle = <0x4e>;
		};

		flashlight_core {
			compatible = "mediatek,flashlight_core";
			linux,phandle = <0x4f>;
			phandle = <0x4f>;
		};

		flashlights_lm3642 {
			compatible = "mediatek,flashlights_lm3642";
			decouple = <0x01>;
			linux,phandle = <0x50>;
			phandle = <0x50>;

			channel@1 {
				type = <0x00>;
				ct = <0x00>;
				part = <0x00>;
			};
		};

		seninf_top@15008000 {
			compatible = "mediatek,SENINF_TOP";
			reg = <0x15008000 0x1000>;
			interrupts = <0x00 0x8e 0x08>;
		};

		CAM_0@0x15004000 {
			compatible = "mediatek,CAM_0";
			reg = <0x15004000 0x1000>;
			interrupts = <0x00 0x8b 0x08>;
		};

		CAM_1@0x15005000 {
			compatible = "mediatek,CAM_1";
			reg = <0x15005000 0x1000>;
		};

		VENC@0x15009000 {
			compatible = "mediatek,VENC";
			reg = <0x15009000 0x1000>;
			interrupts = <0x00 0x8a 0x08>;
		};

		VDEC@0x1500B000 {
			compatible = "mediatek,VDEC";
			reg = <0x1500b000 0x1000>;
			interrupts = <0x00 0x89 0x08>;
		};

		SMI_LARB1@0x15001000 {
			cell-index = <0x01>;
			compatible = "mediatek,SMI_LARB1\0mediatek,smi_larb";
			reg = <0x15001000 0x1000>;
			interrupts = <0x00 0x88 0x08>;
			linux,phandle = <0x1c>;
			phandle = <0x1c>;
		};

		IMGSYS_CONFIG@0x15000000 {
			compatible = "mediatek,IMGSYS_CONFIG";
			reg = <0x15000000 0x1000>;
		};

		hwmsensor@0 {
			compatible = "mediatek,hwmsensor";
		};

		gsensor@0 {
			compatible = "mediatek,gsensor";
		};

		als_ps@0 {
			compatible = "mediatek,als_ps";
			linux,phandle = <0x51>;
			phandle = <0x51>;
		};

		m_acc_pl@0 {
			compatible = "mediatek,m_acc_pl";
		};

		m_alsps_pl@0 {
			compatible = "mediatek,m_alsps_pl";
		};

		sensorHub@0 {
			compatible = "mediatek,sensorHub";
		};

		shf@0 {
			compatible = "mediatek,shf";
		};

		m_batch_pl@0 {
			compatible = "mediatek,m_batch_pl";
		};

		gyroscope@0 {
			compatible = "mediatek,gyroscope";
			linux,phandle = <0x52>;
			phandle = <0x52>;
		};

		m_gyro_pl@0 {
			compatible = "mediatek,m_gyro_pl";
		};

		barometer@0 {
			compatible = "mediatek,barometer";
		};

		m_baro_pl@0 {
			compatible = "mediatek,m_baro_pl";
		};

		msensor@0 {
			compatible = "mediatek,msensor";
		};

		m_mag_pl@0 {
			compatible = "mediatek,m_mag_pl";
		};

		orientation@0 {
			compatible = "mediatek,orientation";
		};

		pedometer@0 {
			compatible = "mediatek,pedometer";
		};

		m_pdr_pl@0 {
			compatible = "mediatek,m_pdr_pl";
		};

		step_counter@0 {
			compatible = "mediatek,step_counter";
		};

		m_step_c_pl@0 {
			compatible = "mediatek,m_step_c_pl";
		};

		in_pocket@0 {
			compatible = "mediatek,in_pocket";
		};

		m_inpk_pl@0 {
			compatible = "mediatek,m_inpk_pl";
		};

		shake@0 {
			compatible = "mediatek,shake";
		};

		m_shk_pl@0 {
			compatible = "mediatek,m_shk_pl";
		};

		face_down@0 {
			compatible = "mediatek,face_down";
		};

		m_fdn_pl@0 {
			compatible = "mediatek,m_fdn_pl";
		};

		activity@0 {
			compatible = "mediatek,activity";
		};

		m_act_pl@0 {
			compatible = "mediatek,m_act_pl";
		};

		heart_rate@0 {
			compatible = "mediatek,heart_rate";
		};

		m_hrm_pl@0 {
			compatible = "mediatek,m_hrm_pl";
		};

		tilt_detector@0 {
			compatible = "mediatek,tilt_detector";
		};

		m_tilt_pl@0 {
			compatible = "mediatek,m_tilt_pl";
		};

		wake_gesture@0 {
			compatible = "mediatek,wake_gesture";
		};

		m_wag_pl@0 {
			compatible = "mediatek,m_wag_pl";
		};

		glance_gesture@0 {
			compatible = "mediatek,glance_gesture";
		};

		m_glg_pl@0 {
			compatible = "mediatek,m_glg_pl";
		};

		pick_up@0 {
			compatible = "mediatek,pick_up";
		};

		m_pkup_pl@0 {
			compatible = "mediatek,m_pkup_pl";
		};

		als {
			compatible = "mediatek, als-eint";
			linux,phandle = <0x53>;
			phandle = <0x53>;
		};

		mtkfb@0 {
			compatible = "mediatek,mtkfb";
			linux,phandle = <0x54>;
			phandle = <0x54>;
		};

		dsi_te {
			compatible = "mediatek, dsi_te-eint";
			linux,phandle = <0x55>;
			phandle = <0x55>;
		};
	};

	MOBICORE {
		compatible = "trustonic,mobicore";
		interrupts = <0x00 0x97 0x01>;
	};

	mt_pmic_regulator {
		compatible = "mediatek,mt_pmic";

		buck_regulators {
			compatible = "mediatek,mt_pmic_buck_regulators";

			buck_vpa {
				regulator-name = "vpa";
				regulator-min-microvolt = <0x7a120>;
				regulator-max-microvolt = <0x37b1d0>;
				regulator-ramp-delay = <0xc350>;
				regulator-enable-ramp-delay = <0xb4>;
				linux,phandle = <0x56>;
				phandle = <0x56>;
			};

			buck_vproc {
				regulator-name = "vproc";
				regulator-min-microvolt = <0xaae60>;
				regulator-max-microvolt = <0x16caf6>;
				regulator-ramp-delay = <0x186a>;
				regulator-enable-ramp-delay = <0xb4>;
				regulator-always-on;
				regulator-boot-on;
				linux,phandle = <0x57>;
				phandle = <0x57>;
			};
		};

		ldo_regulators {
			compatible = "mediatek,mt_pmic_ldo_regulators";

			ldo_vcn28 {
				regulator-name = "vcn28";
				regulator-min-microvolt = <0x1b7740>;
				regulator-max-microvolt = <0x2ab980>;
				regulator-enable-ramp-delay = <0x108>;
				linux,phandle = <0x18>;
				phandle = <0x18>;
			};

			ldo_vtcxo {
				regulator-name = "vtcxo";
				regulator-min-microvolt = <0x2191c0>;
				regulator-max-microvolt = <0x2191c0>;
				regulator-enable-ramp-delay = <0x6e>;
				linux,phandle = <0x22>;
				phandle = <0x22>;
			};

			ldo_va {
				regulator-name = "va";
				regulator-min-microvolt = <0x1b7740>;
				regulator-max-microvolt = <0x2625a0>;
				regulator-enable-ramp-delay = <0x6e>;
				linux,phandle = <0x23>;
				phandle = <0x23>;
			};

			ldo_vcama {
				regulator-name = "vcama";
				regulator-min-microvolt = <0x16e360>;
				regulator-max-microvolt = <0x2ab980>;
				regulator-enable-ramp-delay = <0x108>;
				linux,phandle = <0x1e>;
				phandle = <0x1e>;
			};

			ldo_vcn33_bt {
				regulator-name = "vcn33_bt";
				regulator-min-microvolt = <0x325aa0>;
				regulator-max-microvolt = <0x36ee80>;
				regulator-enable-ramp-delay = <0x108>;
				linux,phandle = <0x19>;
				phandle = <0x19>;
			};

			ldo_vcn33_wifi {
				regulator-name = "vcn33_wifi";
				regulator-min-microvolt = <0x325aa0>;
				regulator-max-microvolt = <0x36ee80>;
				regulator-enable-ramp-delay = <0x108>;
				linux,phandle = <0x1a>;
				phandle = <0x1a>;
			};

			ldo_vio28 {
				regulator-name = "vio28";
				regulator-min-microvolt = <0x2ab980>;
				regulator-max-microvolt = <0x2ab980>;
				regulator-enable-ramp-delay = <0x108>;
				regulator-boot-on;
				linux,phandle = <0x24>;
				phandle = <0x24>;
			};

			ldo_vsim1 {
				regulator-name = "vsim1";
				regulator-min-microvolt = <0x1b7740>;
				regulator-max-microvolt = <0x2dc6c0>;
				regulator-enable-ramp-delay = <0x108>;
				linux,phandle = <0x25>;
				phandle = <0x25>;
			};

			ldo_vsim2 {
				regulator-name = "vsim2";
				regulator-min-microvolt = <0x1b7740>;
				regulator-max-microvolt = <0x2dc6c0>;
				regulator-enable-ramp-delay = <0x108>;
				linux,phandle = <0x26>;
				phandle = <0x26>;
			};

			ldo_vusb {
				regulator-name = "vusb";
				regulator-min-microvolt = <0x325aa0>;
				regulator-max-microvolt = <0x325aa0>;
				regulator-enable-ramp-delay = <0x108>;
				regulator-boot-on;
				linux,phandle = <0x27>;
				phandle = <0x27>;
			};

			ldo_vgp1 {
				regulator-name = "vgp1";
				regulator-min-microvolt = <0x124f80>;
				regulator-max-microvolt = <0x325aa0>;
				regulator-enable-ramp-delay = <0x108>;
				linux,phandle = <0x16>;
				phandle = <0x16>;
			};

			ldo_vgp2 {
				regulator-name = "vgp2";
				regulator-min-microvolt = <0x124f80>;
				regulator-max-microvolt = <0x2dc6c0>;
				regulator-enable-ramp-delay = <0x108>;
				linux,phandle = <0x28>;
				phandle = <0x28>;
			};

			ldo_vemc_3v3 {
				regulator-name = "vemc_3v3";
				regulator-min-microvolt = <0x2dc6c0>;
				regulator-max-microvolt = <0x325aa0>;
				regulator-enable-ramp-delay = <0x108>;
				regulator-boot-on;
				linux,phandle = <0x05>;
				phandle = <0x05>;
			};

			ldo_vcamaf {
				regulator-name = "vcamaf";
				regulator-min-microvolt = <0x124f80>;
				regulator-max-microvolt = <0x325aa0>;
				regulator-enable-ramp-delay = <0x108>;
				linux,phandle = <0x20>;
				phandle = <0x20>;
			};

			ldo_vmc {
				regulator-name = "vmc";
				regulator-min-microvolt = <0x1b7740>;
				regulator-max-microvolt = <0x325aa0>;
				regulator-enable-ramp-delay = <0x2c>;
				linux,phandle = <0x0f>;
				phandle = <0x0f>;
			};

			ldo_vmch {
				regulator-name = "vmch";
				regulator-min-microvolt = <0x2dc6c0>;
				regulator-max-microvolt = <0x325aa0>;
				regulator-enable-ramp-delay = <0x2c>;
				linux,phandle = <0x0e>;
				phandle = <0x0e>;
			};

			ldo_vibr {
				regulator-name = "vibr";
				regulator-min-microvolt = <0x124f80>;
				regulator-max-microvolt = <0x325aa0>;
				regulator-enable-ramp-delay = <0x2c>;
				linux,phandle = <0x29>;
				phandle = <0x29>;
			};

			ldo_vrtc {
				regulator-name = "vrtc";
				regulator-min-microvolt = <0x2ab980>;
				regulator-max-microvolt = <0x2ab980>;
				regulator-enable-ramp-delay = <0x2c>;
				linux,phandle = <0x2a>;
				phandle = <0x2a>;
			};

			ldo_vm {
				regulator-name = "vm";
				regulator-min-microvolt = <0x124f80>;
				regulator-max-microvolt = <0x1b7740>;
				regulator-enable-ramp-delay = <0x108>;
				regulator-boot-on;
				linux,phandle = <0x2b>;
				phandle = <0x2b>;
			};

			ldo_vrf18 {
				regulator-name = "vrf18";
				regulator-min-microvolt = <0x1b7740>;
				regulator-max-microvolt = <0x1b7740>;
				regulator-enable-ramp-delay = <0xdc>;
				linux,phandle = <0x2c>;
				phandle = <0x2c>;
			};

			ldo_vio18 {
				regulator-name = "vio18";
				regulator-min-microvolt = <0x1b7740>;
				regulator-max-microvolt = <0x1b7740>;
				regulator-enable-ramp-delay = <0x108>;
				regulator-boot-on;
				linux,phandle = <0x2d>;
				phandle = <0x2d>;
			};

			ldo_vcamd {
				regulator-name = "vcamd";
				regulator-min-microvolt = <0x124f80>;
				regulator-max-microvolt = <0x1b7740>;
				regulator-enable-ramp-delay = <0x108>;
				linux,phandle = <0x1f>;
				phandle = <0x1f>;
			};

			ldo_vcamio {
				regulator-name = "vcamio";
				regulator-min-microvolt = <0x1b7740>;
				regulator-max-microvolt = <0x1b7740>;
				regulator-enable-ramp-delay = <0xdc>;
				linux,phandle = <0x21>;
				phandle = <0x21>;
			};

			ldo_vgp3 {
				regulator-name = "vgp3";
				regulator-min-microvolt = <0x124f80>;
				regulator-max-microvolt = <0x1b7740>;
				regulator-enable-ramp-delay = <0x108>;
				linux,phandle = <0x2e>;
				phandle = <0x2e>;
			};

			ldo_vcn_1v8 {
				regulator-name = "vcn_1v8";
				regulator-min-microvolt = <0x1b7740>;
				regulator-max-microvolt = <0x1b7740>;
				regulator-enable-ramp-delay = <0x2c>;
				linux,phandle = <0x17>;
				phandle = <0x17>;
			};

			vcanio_ldo_reg {
				linux,phandle = <0x58>;
				phandle = <0x58>;
			};

			vcn33_ldo_reg {
				linux,phandle = <0x59>;
				phandle = <0x59>;
			};
		};

		regulators_supply {
			compatible = "mediatek,mt_pmic_regulator_supply";
			vcn28-supply = <0x18>;
			vtcxo-supply = <0x22>;
			va-supply = <0x23>;
			vcn33_bt-supply = <0x19>;
			vcn33_wifi-supply = <0x1a>;
			vio28-supply = <0x24>;
			vsim1-supply = <0x25>;
			vsim2-supply = <0x26>;
			vusb-supply = <0x27>;
			vgp1-supply = <0x16>;
			vgp2-supply = <0x28>;
			vemc_3v3-supply = <0x05>;
			vcamaf-supply = <0x20>;
			vmc-supply = <0x0f>;
			vmch-supply = <0x0e>;
			vibr-supply = <0x29>;
			vrtc-supply = <0x2a>;
			vm-supply = <0x2b>;
			vrf18-supply = <0x2c>;
			vio18-supply = <0x2d>;
			vcamd-supply = <0x1f>;
			vcamio-supply = <0x21>;
			vgp3-supply = <0x2e>;
			vcn_1v8-supply = <0x17>;
		};
	};

	rf_clock_buffer {
		compatible = "mediatek,rf_clock_buffer";
		#mediatek,clkbuf-quantity = <0x04>;
		#mediatek,clkbuf-config = <0x02 0x01 0x01 0x01>;
		linux,phandle = <0x5a>;
		phandle = <0x5a>;
	};

	firmware {

		android {
			compatible = "android,firmware";

			vbmeta {
				compatible = "android,vbmeta";
				parts = "vbmeta,boot,system,vendor,recovery";
			};

			fstab {
				compatible = "android,fstab";

				vendor {
					compatible = "android,vendor";
					dev = "/dev/block/platform/bootdevice/by-name/vendor";
					type = "ext4";
					mnt_flags = "ro";
					fsmgr_flags = "wait,avb";
				};
			};
		};
	};

	odm {
		compatible = "simple-bus";
		linux,phandle = <0x5b>;
		phandle = <0x5b>;
	};

	trusty {
		compatible = "android,trusty-smc-v1";
		ranges;
		#address-cells = <0x02>;
		#size-cells = <0x02>;

		irq {
			compatible = "android,trusty-irq-v1";
			ppi-interrupt-parent = <0x01>;
		};

		log {
			compatible = "android,trusty-log-v1";
		};

		virtio {
			compatible = "android,trusty-virtio-v1";
		};

		mtee {
			compatible = "mediatek,trusty-mtee-v1";
		};
	};

	__symbols__ {
		chosen = "/chosen";
		msdc0 = "/msdc@11120000";
		msdc1 = "/msdc@11130000";
		msdc1_ins = "/msdc1_ins@0";
		cpu0 = "/cpus/cpu@0";
		cpu1 = "/cpus/cpu@1";
		cpu2 = "/cpus/cpu@2";
		cpu3 = "/cpus/cpu@3";
		reserved_memory = "/reserved-memory";
		gic = "/interrupt-controller@10210000";
		bus = "/bus";
		bat_meter = "/bus/bat_meter";
		bat_comm = "/bus/bat_comm";
		keypad = "/bus/keypad@10002000";
		gpio_usage_mapping = "/bus/gpio";
		gpio = "/bus/gpio@0x10005000";
		cpu_dbgapb = "/bus/cpu_dbgapb@10170000";
		eintc = "/bus/eintc@1000b000";
		ap_ccif0 = "/bus/ap_ccif0@1000C000";
		mcucfg = "/bus/mcucfg@10200000";
		sys_cirq = "/bus/sys_cirq@10202000";
		ap_dma = "/bus/dma@0x11000000";
		auxadc = "/bus/adc_hw@11003000";
		syscfg_pctl_a = "/bus/syscfg_pctl_a@0x10005000";
		pio = "/bus/pinctrl@0x10005000";
		msdc0_pins_default = "/bus/pinctrl@0x10005000/msdc0@default";
		msdc0_pins_hs200 = "/bus/pinctrl@0x10005000/msdc0@hs200";
		msdc0_register_setting_default = "/bus/pinctrl@0x10005000/msdc0@register_default";
		mmc1_pins_insert_default = "/bus/pinctrl@0x10005000/mmc1_ins_default";
		mmc1_pins_insert_cfg = "/bus/pinctrl@0x10005000/mmc1_ins_cfg";
		msdc1_pins_default = "/bus/pinctrl@0x10005000/msdc1@default";
		msdc1_pins_sdr104 = "/bus/pinctrl@0x10005000/msdc1@sdr104";
		msdc1_pins_sdr50 = "/bus/pinctrl@0x10005000/msdc1@sdr50";
		msdc1_pins_ddr50 = "/bus/pinctrl@0x10005000/msdc1@ddr50";
		msdc1_register_setting_default = "/bus/pinctrl@0x10005000/msdc1@register_default";
		i2c0 = "/bus/i2c@11009000";
		i2c1 = "/bus/i2c@1100a000";
		i2c2 = "/bus/i2c@1100b000";
		touch = "/bus/touch@0";
		accdet = "/bus/accdet";
		gse_1 = "/bus/gse_1";
		consys = "/bus/consys@18070000";
		usb0 = "/bus/USB0@0x11100000";
		usbiddig = "/bus/usbiddig";
		usbphy0 = "/bus/usbphy@0";
		audgpio = "/bus/mt_soc_dl1_pcm@11140000";
		mmsys_config = "/bus/mmsys_config@14000000";
		lcm = "/bus/lcm";
		nfc = "/bus/nfc";
		smi_larb0 = "/bus/SMI_LARB0@0x14016000";
		kd_camera_hw1 = "/bus/kd_camera_hw1@15008000";
		kd_camera_hw2 = "/bus/kd_camera_hw2@15008000";
		flashlight_core = "/bus/flashlight_core";
		flashlights_lm3642 = "/bus/flashlights_lm3642";
		smi_larb1 = "/bus/SMI_LARB1@0x15001000";
		alsps = "/bus/als_ps@0";
		gyro = "/bus/gyroscope@0";
		als = "/bus/als";
		mtkfb = "/bus/mtkfb@0";
		dsi_te = "/bus/dsi_te";
		mt_pmic_vpa_buck_reg = "/mt_pmic_regulator/buck_regulators/buck_vpa";
		mt_pmic_vproc_buck_reg = "/mt_pmic_regulator/buck_regulators/buck_vproc";
		mt_pmic_vcn28_ldo_reg = "/mt_pmic_regulator/ldo_regulators/ldo_vcn28";
		mt_pmic_vtcxo_ldo_reg = "/mt_pmic_regulator/ldo_regulators/ldo_vtcxo";
		mt_pmic_va_ldo_reg = "/mt_pmic_regulator/ldo_regulators/ldo_va";
		mt_pmic_vcama_ldo_reg = "/mt_pmic_regulator/ldo_regulators/ldo_vcama";
		mt_pmic_vcn33_bt_ldo_reg = "/mt_pmic_regulator/ldo_regulators/ldo_vcn33_bt";
		mt_pmic_vcn33_wifi_ldo_reg = "/mt_pmic_regulator/ldo_regulators/ldo_vcn33_wifi";
		mt_pmic_vio28_ldo_reg = "/mt_pmic_regulator/ldo_regulators/ldo_vio28";
		mt_pmic_vsim1_ldo_reg = "/mt_pmic_regulator/ldo_regulators/ldo_vsim1";
		mt_pmic_vsim2_ldo_reg = "/mt_pmic_regulator/ldo_regulators/ldo_vsim2";
		mt_pmic_vusb_ldo_reg = "/mt_pmic_regulator/ldo_regulators/ldo_vusb";
		mt_pmic_vgp1_ldo_reg = "/mt_pmic_regulator/ldo_regulators/ldo_vgp1";
		mt_pmic_vgp2_ldo_reg = "/mt_pmic_regulator/ldo_regulators/ldo_vgp2";
		mt_pmic_vemc_3v3_ldo_reg = "/mt_pmic_regulator/ldo_regulators/ldo_vemc_3v3";
		mt_pmic_vcamaf_ldo_reg = "/mt_pmic_regulator/ldo_regulators/ldo_vcamaf";
		mt_pmic_vmc_ldo_reg = "/mt_pmic_regulator/ldo_regulators/ldo_vmc";
		mt_pmic_vmch_ldo_reg = "/mt_pmic_regulator/ldo_regulators/ldo_vmch";
		mt_pmic_vibr_ldo_reg = "/mt_pmic_regulator/ldo_regulators/ldo_vibr";
		mt_pmic_vrtc_ldo_reg = "/mt_pmic_regulator/ldo_regulators/ldo_vrtc";
		mt_pmic_vm_ldo_reg = "/mt_pmic_regulator/ldo_regulators/ldo_vm";
		mt_pmic_vrf18_ldo_reg = "/mt_pmic_regulator/ldo_regulators/ldo_vrf18";
		mt_pmic_vio18_ldo_reg = "/mt_pmic_regulator/ldo_regulators/ldo_vio18";
		mt_pmic_vcamd_ldo_reg = "/mt_pmic_regulator/ldo_regulators/ldo_vcamd";
		mt_pmic_vcamio_ldo_reg = "/mt_pmic_regulator/ldo_regulators/ldo_vcamio";
		mt_pmic_vgp3_ldo_reg = "/mt_pmic_regulator/ldo_regulators/ldo_vgp3";
		mt_pmic_vcn_1v8_ldo_reg = "/mt_pmic_regulator/ldo_regulators/ldo_vcn_1v8";
		mt_pmic_vcanio_ldo_reg = "/mt_pmic_regulator/ldo_regulators/vcanio_ldo_reg";
		mt_pmic_vcn33_ldo_reg = "/mt_pmic_regulator/ldo_regulators/vcn33_ldo_reg";
		rf_clock_buffer_ctrl = "/rf_clock_buffer";
		odm = "/odm";
	};
};
